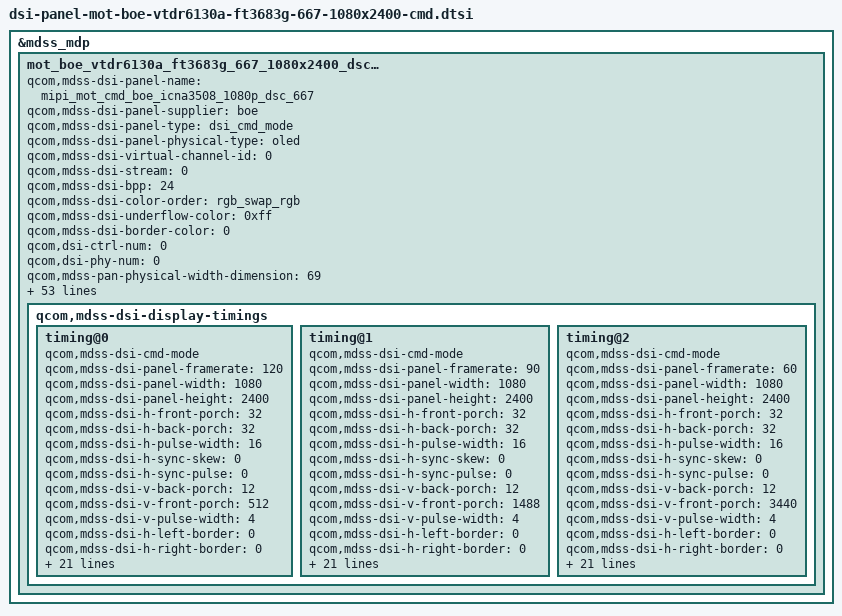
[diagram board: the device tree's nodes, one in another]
/* Copyright (c) 2019-2020, The Linux Foundation. All rights reserved.
 *
 * This program is free software; you can redistribute it and/or modify
 * it under the terms of the GNU General Public License version 2 and
 * only version 2 as published by the Free Software Foundation.
 *
 * This program is distributed in the hope that it will be useful,
 * but WITHOUT ANY WARRANTY; without even the implied warranty of
 * MERCHANTABILITY or FITNESS FOR A PARTICULAR PURPOSE.  See the
 * GNU General Public License for more details.
 */
&mdss_mdp {
	mot_boe_vtdr6130a_ft3683g_667_1080x2400_dsc_cmd: qcom,mdss_dsi_mot_boe_vtdr6130a_ft3683g_667_1080x2400_dsc_cmd {
		qcom,mdss-dsi-panel-name = "mipi_mot_cmd_boe_icna3508_1080p_dsc_667";
		qcom,mdss-dsi-panel-supplier = "boe";
		qcom,mdss-dsi-panel-type = "dsi_cmd_mode";
		qcom,mdss-dsi-panel-physical-type = "oled";
		qcom,mdss-dsi-virtual-channel-id = <0>;
		qcom,mdss-dsi-stream = <0>;
		qcom,mdss-dsi-bpp = <24>;
		qcom,mdss-dsi-color-order = "rgb_swap_rgb";
		qcom,mdss-dsi-underflow-color = <0xff>;
		qcom,mdss-dsi-border-color = <0>;

		qcom,dsi-ctrl-num = <0>;
		qcom,dsi-phy-num = <0>;
		qcom,mdss-pan-physical-width-dimension = <69>;
		qcom,mdss-pan-physical-height-dimension = <154>;

		qcom,mdss-dsi-traffic-mode = "non_burst_sync_event";
		qcom,mdss-dsi-bllp-eof-power-mode;
		qcom,mdss-dsi-bllp-power-mode;
		qcom,mdss-dsi-lane-0-state;
		qcom,mdss-dsi-lane-1-state;
		qcom,mdss-dsi-lane-2-state;
		qcom,mdss-dsi-lane-3-state;
		qcom,mdss-dsi-dma-trigger = "trigger_sw";
		qcom,mdss-dsi-mdp-trigger = "none";
		qcom,mdss-dsi-reset-sequence = <0 0>, <1 2>, <0 2>, <1 20>;

		qcom,mdss-dsi-tx-eot-append;
		qcom,mdss-dsi-te-pin-select = <1>;
		qcom,mdss-dsi-te-dcs-command = <1>;
		qcom,mdss-dsi-te-check-enable;
		qcom,mdss-dsi-te-using-te-pin;

		qcom,mdss-dsi-dc-off-command = [
				15 00 00 00 00 00 02 5E 00];
		qcom,mdss-dsi-dc-off-command-state = "dsi_hs_mode";
		qcom,mdss-dsi-dc-on-command = [
				15 00 00 00 00 00 02 5E 01];
		qcom,mdss-dsi-dc-on-command-state = "dsi_hs_mode";

		qcom,mdss-dsi-hbm-detect-fps;
		qcom,mdss-dsi-hbm-on-command = [
				39 00 00 40 00 00 03 51 0F FF
				39 00 00 00 00 00 02 62 00];
		qcom,mdss-dsi-hbm-on-command-state = "dsi_hs_mode";
		qcom,mdss-dsi-hbm-off-command = [
				39 00 00 40 00 00 02 62 00
				39 00 00 40 00 00 03 51 05 2A];
		qcom,mdss-dsi-hbm-off-command-state = "dsi_hs_mode";

		qcom,mdss-dsi-hbm-fod;
		qcom,mdss-dsi-hbm-fod-on-command = [
				39 00 00 40 00 00 05 63 10 00 05 29
				39 00 00 00 00 00 02 62 03];
		qcom,mdss-dsi-hbm-fod-on-command-state = "dsi_hs_mode";

		qcom,mdss-dsi-panel-lhbm-wait-fps-valid;
		qcom,mdss-dsi-panel-local-hbm-wait-fps-count = <30>;
		qcom,mdss-dsi-panel-local-hbm-wait-fps-interval = <1>;
		qcom,mdss-dsi-panel-lhbm-not-allowed-fps-list = <60 90>;

		qcom,mdss-dsi-panel-local-hbm-enabled;
		qcom,mdss-dsi-panel-local-hbm-DC-HYBIRD-THRESHOLD-BL = <1321>; //0x0529
		qcom,mdss-dsi-panel-local-hbm-alpha-register = <0x63>;
		qcom,mdss-dsi-panel-local-hbm-alpha-size = <4096>;
		qcom,mdss-dsi-panel-bl-num = <1>;

		qcom,mdss-dsi-display-timings {
			timing@0 {
				qcom,mdss-dsi-cmd-mode;
				qcom,mdss-dsi-panel-framerate = <120>;
				qcom,mdss-dsi-panel-width = <1080>;
				qcom,mdss-dsi-panel-height = <2400>;
				qcom,mdss-dsi-h-front-porch = <32>;
				qcom,mdss-dsi-h-back-porch = <32>;
				qcom,mdss-dsi-h-pulse-width = <16>;
				qcom,mdss-dsi-h-sync-skew = <0>;
				qcom,mdss-dsi-h-sync-pulse = <0>;
				qcom,mdss-dsi-v-back-porch = <12>;
				qcom,mdss-dsi-v-front-porch = <512>;
				qcom,mdss-dsi-v-pulse-width = <4>;
				qcom,mdss-dsi-h-left-border = <0>;
				qcom,mdss-dsi-h-right-border = <0>;
				qcom,mdss-dsi-v-top-border = <0>;
				qcom,mdss-dsi-v-bottom-border = <0>;
				qcom,mdss-dsi-panel-jitter = <0x20 0xa>; /* 120fps +/- 2 */
				qcom,mdss-dsi-timing-switch-command = [
					    39 01 00 00 00 00 02 6C 01];

				qcom,mdss-dsi-on-command = [
						39 01 00 00 00 00 02 03 01
						39 01 00 00 00 00 02 35 00
						39 01 00 00 00 00 02 53 20
						39 01 00 00 00 00 03 51 0D BA
						39 01 00 00 00 00 02 5E 00
						39 01 00 00 00 00 02 59 09
						39 01 00 00 00 00 02 62 00
						39 01 00 00 00 00 02 6C 01
						39 01 00 00 00 00 02 6D 00
						39 01 00 00 00 00 02 6F 02
						39 01 00 00 00 00 03 F0 AA 12
						39 01 00 00 00 00 02 65 01
						39 01 00 00 00 00 02 C7 7B

						39 01 00 00 00 00 03 F0 AA 12
						39 01 00 00 00 00 02 65 10
						39 01 00 00 00 00 02 BF 40
						39 01 00 00 00 00 02 65 10
						39 01 00 00 00 00 02 D9 40
						39 01 00 00 00 00 02 65 10
						39 01 00 00 00 00 02 DF 40
						39 01 00 00 00 00 02 65 10
						39 01 00 00 00 00 02 EB 40

						39 01 00 00 00 00 03 FF 5A 80
						39 01 00 00 00 00 02 65 0A
						39 01 00 00 00 00 02 F9 A8
						39 01 00 00 00 00 03 FF 5A 81
						39 01 00 00 00 00 02 65 06
						39 01 00 00 00 00 02 F3 87
						39 01 00 00 00 00 02 65 09
						39 01 00 00 00 00 02 F3 00
						39 01 00 00 00 00 02 65 0A
						39 01 00 00 00 00 02 F3 10
						39 01 00 00 00 00 02 65 10
						39 01 00 00 00 00 02 F3 10

						39 01 00 00 5A 00 01 11
						39 01 00 00 00 00 03 F0 AA 12
						39 01 00 00 00 00 02 65 10
						39 01 00 00 00 00 02 BF 0B
						39 01 00 00 00 00 02 65 10
						39 01 00 00 00 00 02 D9 0B
						39 01 00 00 00 00 02 65 10
						39 01 00 00 00 00 02 DF 0B
						39 01 00 00 00 00 02 65 10
						39 01 00 00 00 00 02 EB 0B
						39 01 00 00 00 00 03 F0 AA 00
						39 01 00 00 00 00 03 FF 5A 00
						39 01 00 00 05 00 01 29];	/* display on */
				qcom,mdss-dsi-off-command = [
					05 01 00 00 00 00 01 28		/* display_off */
					05 01 00 00 78 00 01 10];	/* enter sleep mode */

				qcom,mdss-dsi-on-command-state = "dsi_lp_mode";
				qcom,mdss-dsi-off-command-state = "dsi_lp_mode";
				qcom,mdss-dsi-timing-switch-command-state =
					"dsi_lp_mode";
				qcom,compression-mode = "dsc";
				qcom,mdss-dsc-version = <0x11>;
				qcom,mdss-dsc-slice-height = <12>;
				qcom,mdss-dsc-slice-width = <540>;
				qcom,mdss-dsc-slice-per-pkt = <2>;
				qcom,mdss-dsc-bit-per-component = <8>;
				qcom,mdss-dsc-bit-per-pixel = <8>;
				qcom,mdss-dsc-block-prediction-enable;
			};
			timing@1{
				qcom,mdss-dsi-cmd-mode;
				qcom,mdss-dsi-panel-framerate = <90>;
				qcom,mdss-dsi-panel-width = <1080>;
				qcom,mdss-dsi-panel-height = <2400>;
				qcom,mdss-dsi-h-front-porch = <32>;
				qcom,mdss-dsi-h-back-porch = <32>;
				qcom,mdss-dsi-h-pulse-width = <16>;
				qcom,mdss-dsi-h-sync-skew = <0>;
				qcom,mdss-dsi-h-sync-pulse = <0>;
				qcom,mdss-dsi-v-back-porch = <12>;
				qcom,mdss-dsi-v-front-porch = <1488>;
				qcom,mdss-dsi-v-pulse-width = <4>;
				qcom,mdss-dsi-h-left-border = <0>;
				qcom,mdss-dsi-h-right-border = <0>;
				qcom,mdss-dsi-v-top-border = <0>;
				qcom,mdss-dsi-v-bottom-border = <0>;
				qcom,mdss-dsi-panel-jitter = <0x20 0xa>; /* 90fps +/- 2 */
				qcom,mdss-dsi-timing-switch-command = [
					15 01 00 00 00 00 02 6C 02];

				qcom,mdss-dsi-on-command = [
						39 01 00 00 00 00 02 03 01
						39 01 00 00 00 00 02 35 00
						39 01 00 00 00 00 02 53 20
						39 01 00 00 00 00 03 51 00 00
						39 01 00 00 00 00 02 5E 00
						39 01 00 00 00 00 02 59 09
						39 01 00 00 00 00 02 62 00
						39 01 00 00 00 00 02 6C 01
						39 01 00 00 00 00 02 6D 00
						39 01 00 00 00 00 02 6F 02
						39 01 00 00 00 00 03 F0 AA 12
						39 01 00 00 00 00 02 65 01
						39 01 00 00 00 00 02 C7 7B

						39 01 00 00 00 00 03 F0 AA 12
						39 01 00 00 00 00 02 65 10
						39 01 00 00 00 00 02 BF 40
						39 01 00 00 00 00 02 65 10
						39 01 00 00 00 00 02 D9 40
						39 01 00 00 00 00 02 65 10
						39 01 00 00 00 00 02 DF 40
						39 01 00 00 00 00 02 65 10
						39 01 00 00 00 00 02 EB 40

						39 01 00 00 00 00 03 FF 5A 80
						39 01 00 00 00 00 02 65 0A
						39 01 00 00 00 00 02 F9 A8
						39 01 00 00 00 00 03 FF 5A 81
						39 01 00 00 00 00 02 65 06
						39 01 00 00 00 00 02 F3 87
						39 01 00 00 00 00 02 65 09
						39 01 00 00 00 00 02 F3 00
						39 01 00 00 00 00 02 65 0A
						39 01 00 00 00 00 02 F3 10
						39 01 00 00 00 00 02 65 10
						39 01 00 00 00 00 02 F3 10

						39 01 00 00 5A 00 01 11
						39 01 00 00 00 00 03 F0 AA 12
						39 01 00 00 00 00 02 65 10
						39 01 00 00 00 00 02 BF 0B
						39 01 00 00 00 00 02 65 10
						39 01 00 00 00 00 02 D9 0B
						39 01 00 00 00 00 02 65 10
						39 01 00 00 00 00 02 DF 0B
						39 01 00 00 00 00 02 65 10
						39 01 00 00 00 00 02 EB 0B
						39 01 00 00 00 00 03 F0 AA 00
						39 01 00 00 00 00 03 FF 5A 00
						39 01 00 00 05 00 01 29];	/* display on */
				qcom,mdss-dsi-off-command = [
					05 01 00 00 00 00 01 28		/* display_off */
					05 01 00 00 78 00 01 10];	/* enter sleep mode */

				qcom,mdss-dsi-on-command-state = "dsi_lp_mode";
				qcom,mdss-dsi-off-command-state = "dsi_lp_mode";
				qcom,mdss-dsi-timing-switch-command-state =
					"dsi_lp_mode";
				qcom,compression-mode = "dsc";
				qcom,mdss-dsc-version = <0x11>;
				qcom,mdss-dsc-slice-height = <12>;
				qcom,mdss-dsc-slice-width = <540>;
				qcom,mdss-dsc-slice-per-pkt = <2>;
				qcom,mdss-dsc-bit-per-component = <8>;
				qcom,mdss-dsc-bit-per-pixel = <8>;
				qcom,mdss-dsc-block-prediction-enable;
			};
			timing@2{
				qcom,mdss-dsi-cmd-mode;
				qcom,mdss-dsi-panel-framerate = <60>;
				qcom,mdss-dsi-panel-width = <1080>;
				qcom,mdss-dsi-panel-height = <2400>;
				qcom,mdss-dsi-h-front-porch = <32>;
				qcom,mdss-dsi-h-back-porch = <32>;
				qcom,mdss-dsi-h-pulse-width = <16>;
				qcom,mdss-dsi-h-sync-skew = <0>;
				qcom,mdss-dsi-h-sync-pulse = <0>;
				qcom,mdss-dsi-v-back-porch = <12>;
				qcom,mdss-dsi-v-front-porch = <3440>;
				qcom,mdss-dsi-v-pulse-width = <4>;
				qcom,mdss-dsi-h-left-border = <0>;
				qcom,mdss-dsi-h-right-border = <0>;
				qcom,mdss-dsi-v-top-border = <0>;
				qcom,mdss-dsi-v-bottom-border = <0>;
				qcom,mdss-dsi-panel-jitter = <0x20 0xa>; /* 60fps +/- 2 */
				qcom,mdss-dsi-timing-switch-command = [
					15 01 00 00 0b 00 02 6C 03];

				qcom,mdss-dsi-on-command = [
						39 01 00 00 00 00 02 03 01
						39 01 00 00 00 00 02 35 00
						39 01 00 00 00 00 02 53 20
						39 01 00 00 00 00 03 51 0D BA
						39 01 00 00 00 00 02 5E 00
						39 01 00 00 00 00 02 59 09
						39 01 00 00 00 00 02 62 00
						39 01 00 00 00 00 02 6C 01
						39 01 00 00 00 00 02 6D 00
						39 01 00 00 00 00 02 6F 02
						39 01 00 00 00 00 03 F0 AA 12
						39 01 00 00 00 00 02 65 01
						39 01 00 00 00 00 02 C7 7B

						39 01 00 00 00 00 03 F0 AA 12
						39 01 00 00 00 00 02 65 10
						39 01 00 00 00 00 02 BF 40
						39 01 00 00 00 00 02 65 10
						39 01 00 00 00 00 02 D9 40
						39 01 00 00 00 00 02 65 10
						39 01 00 00 00 00 02 DF 40
						39 01 00 00 00 00 02 65 10
						39 01 00 00 00 00 02 EB 40

						39 01 00 00 00 00 03 FF 5A 80
						39 01 00 00 00 00 02 65 0A
						39 01 00 00 00 00 02 F9 A8
						39 01 00 00 00 00 03 FF 5A 81
						39 01 00 00 00 00 02 65 06
						39 01 00 00 00 00 02 F3 87
						39 01 00 00 00 00 02 65 09
						39 01 00 00 00 00 02 F3 00
						39 01 00 00 00 00 02 65 0A
						39 01 00 00 00 00 02 F3 10
						39 01 00 00 00 00 02 65 10
						39 01 00 00 00 00 02 F3 10

						39 01 00 00 5A 00 01 11
						39 01 00 00 00 00 03 F0 AA 12
						39 01 00 00 00 00 02 65 10
						39 01 00 00 00 00 02 BF 0B
						39 01 00 00 00 00 02 65 10
						39 01 00 00 00 00 02 D9 0B
						39 01 00 00 00 00 02 65 10
						39 01 00 00 00 00 02 DF 0B
						39 01 00 00 00 00 02 65 10
						39 01 00 00 00 00 02 EB 0B
						39 01 00 00 00 00 03 F0 AA 00
						39 01 00 00 00 00 03 FF 5A 00
						39 01 00 00 05 00 01 29];	/* display on */
				qcom,mdss-dsi-off-command = [
					05 01 00 00 00 00 01 28		/* display_off */
					05 01 00 00 78 00 01 10];	/* enter sleep mode */

				qcom,mdss-dsi-on-command-state = "dsi_lp_mode";
				qcom,mdss-dsi-off-command-state = "dsi_lp_mode";
				qcom,mdss-dsi-timing-switch-command-state =
					"dsi_lp_mode";
				qcom,compression-mode = "dsc";
				qcom,mdss-dsc-version = <0x11>;
				qcom,mdss-dsc-slice-height = <12>;
				qcom,mdss-dsc-slice-width = <540>;
				qcom,mdss-dsc-slice-per-pkt = <2>;
				qcom,mdss-dsc-bit-per-component = <8>;
				qcom,mdss-dsc-bit-per-pixel = <8>;
				qcom,mdss-dsc-block-prediction-enable;
			};
		};
	};
};
